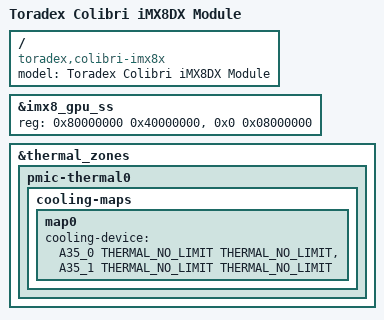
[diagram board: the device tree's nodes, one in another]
// SPDX-License-Identifier: GPL-2.0-or-later OR X11
/*
 * Copyright 2018-2021 Toradex
 */

#include "imx8dx.dtsi"
#include "imx8x-colibri.dtsi"

/ {
	model = "Toradex Colibri iMX8DX Module";
	compatible = "toradex,colibri-imx8x", "fsl,imx8dx";
};

&imx8_gpu_ss {
	reg = <0x80000000 0x40000000>, <0x0 0x08000000>;
	reg-names = "phys_baseaddr", "contiguous_mem";
};

&thermal_zones {
	pmic-thermal0 {
		cooling-maps {
			map0 {
				cooling-device =
				<&A35_0 THERMAL_NO_LIMIT THERMAL_NO_LIMIT>,
				<&A35_1 THERMAL_NO_LIMIT THERMAL_NO_LIMIT>;
			};
		};
	};
};
